# M55M1 register map
File version: 1.0
Registers are 32-bit, read-write, reset 0x0 unless marked. A register's access mark holds for its fields unless they carry their own. Offsets are from the block's base; [hi:lo] are bit positions.

## HSOTG_NS — HSOTG Register Map
Base 0x50259000
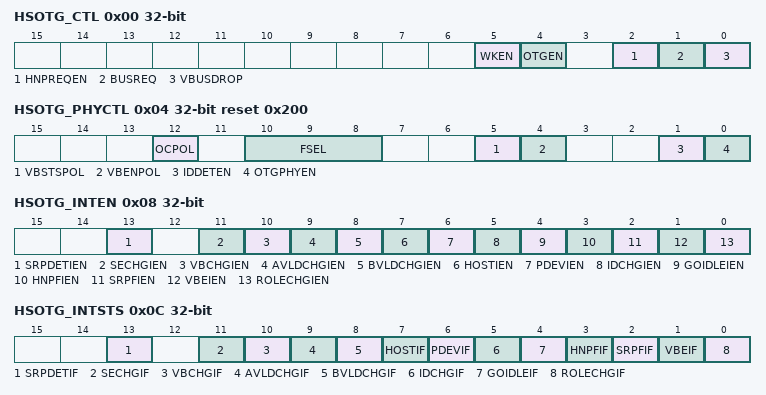
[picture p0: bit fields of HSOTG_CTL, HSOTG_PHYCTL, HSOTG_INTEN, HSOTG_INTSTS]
0x00 HSOTG_CTL — HSOTG Control Register
  [5] WKEN — OTG ID Pin Wake-up Enable Bit
    0=OTG ID pin status change wake-up function Disabled; 1=OTG ID pin status change wake-up function Enabled
  [4] OTGEN — OTG Function Enable Bit. User needs to set this bit to enable OTG function while the USB frame configured as OTG device. When the USB frame is not configured as OTG device, this bit is must be low.
    0=OTG function Disabled; 1=OTG function Enabled
  [2] HNPREQEN — OTG HNP Request Enable Bit. When the USB frame acts as A-device, set this bit when A-device allows to process HNP protocolA-device changes role from Host to Peripheral. This bit will be cleared when OTG state changes from a_suspend to a_peripheral or goes back to a_idle state. When the USB frame acts as B-device, set this bit after the OTG A-device successfully sends a SetFeature (b_hnp_enable) command to the OTG B-device to start role changeB-device changes role from Peripheral to Host. This bit will be cleared when OTG state changes from b_peripheral to b_wait_acon or goes back to b_idle state. Note: Refer to OTG specification to get a_suspend, a_peripheral, a_idle and b_idle state.
    0=HNP request Disabled; 1=HNP request Enabled (A-device can change role from Host to Peripheral or B-device can change role from Peripheral to Host)
  [1] BUSREQ — OTG Bus Request. If OTG A-device wants to do data transfers via USB bus, setting this bit will drive VBUS high to detect USB device connection. If user won't use the bus any more, clearing this bit will drop VBUS to save power. This bit will be cleared when A-device goes to A_wait_vfall state. This bit will be also cleared if VBUSDROP (HSOTG_CTL[0]) bit is set or IDSTS (HSOTG_STATUS[1]) changed. If user of an OTG-B Device wants to request VBUS, setting this bit will run SRP protocol. This bit will be cleared if SRP failure (OTG A-device does not provide VBUS after B-device issues SRP in specified interval, defined in OTG specification). This bit will be also cleared if VBUSDROP (HSOTG_CTL[0]) bit is set or IDSTS (HSOTG_STATUS[1]) changed.
    0=Not launch VBUS in OTG A-device or not request SRP in OTG B-device; 1=Launch VBUS in OTG A-device or request SRP in OTG B-device
  [0] VBUSDROP — Drop VBUS Control. If user application running on this OTG A-device wants to conserve power, set this bit to drop VBUS. BUSREQ (HSOTG_CTL[1]) will be also cleared no matter A-device or B-device.
    0=Not drop the VBUS; 1=Drop the VBUS
0x04 HSOTG_PHYCTL reset 0x200 — HSOTG PHY Control Register
  [12] OCPOL — Over Current Polarity. The polarity of off-chip USB VBUS power switch's overcurrent signal depends on the selected component. A USB_VBUS_ST pin is used to monitor the signal of the off-chip USB VBUS power switch's overcurrent signal.Set this bit as following according to the polarity of off-chip USB VBUS power switch's overcurrent. The overcurrent signal be used in USB HOST.
    0=The polarity of off-chip USB VBUS power switch's overcurrent is low; 1=The polarity of off-chip USB VBUS power switch's overcurrent is high
  [10:8] FSEL — Reference Clock Frequency Select. Selects OTG PHY reference clock frequency .
    0=Reference clock is 19.2 MHz; 1=Reference clock is 20 MHz; 2=Reference clock is 24 MHz; 3=Reference clock is 16 MHz; 6=Reference clock is 26MHz; 7=Reference clock is 32 MHz
  [5] VBSTSPOL — Off-chip USB VBUS Power Switch Status Polarity. The polarity of off-chip USB VBUS power switch valid signal depends on the selected component. A USB_VBUS_ST pin is used to monitor the valid signal of the off-chip USB VBUS power switch. Set this bit as following according to the polarity of off-chip USB VBUS power switch.
    0=The polarity of off-chip USB VBUS power switch valid status is high; 1=The polarity of off-chip USB VBUS power switch valid status is low
  [4] VBENPOL — Off-chip USB VBUS Power Switch Enable Polarity. The OTG controller will enable off-chip USB VBUS power switch to provide VBUS power when need. A USB_VBUS_EN pin is used to control the off-chip USB VBUS power switch. The polarity of enabling off-chip USB VBUS power switch (high active or low active) depends on the selected component. Set this bit as following according to the polarity of off-chip USB VBUS power switch.
    0=The off-chip USB VBUS power switch enable is active high; 1=The off-chip USB VBUS power switch enable is active low
  [1] IDDETEN — ID Detection Enable Bit
    0=Detect ID pin status Disabled; 1=Detect ID pin status Enabled
  [0] OTGPHYEN — OTG PHY Enable Bit. When the USB frame is configured as either OTG device or ID dependent, user needs to set this bit before using OTG function. If device is configured as neither OTG device nor ID dependent, this bit is 'don't care'.
    0=OTG PHY Disabled; 1=OTG PHY Enabled
0x08 HSOTG_INTEN — HSOTG Interrupt Enable Register
  [13] SRPDETIEN — SRP Detected Interrupt Enable Bit
    0=Interrupt Disabled; 1=Interrupt Enabled
  [11] SECHGIEN — SESSEND Status Changed Interrupt Enable Bit. If this bit is set to 1 and SESSEND (HSOTG_STATUS[2]) status is changed from high to low or from low to high, an interrupt will be asserted.
    0=Interrupt Disabled; 1=Interrupt Enabled
  [10] VBCHGIEN — VBUSVLD Status Changed Interrupt Enable Bit. If this bit is set to 1 and VBUSVLD (HSOTG_STATUS[5]) status is changed from high to low or from low to high, an interrupt will be asserted.
    0=Interrupt Disabled; 1=Interrupt Enabled
  [9] AVLDCHGIEN — A-device Session Valid Status Changed Interrupt Enable Bit. If this bit is set to 1 and AVLD (HSOTG_STATUS[4]) status is changed from high to low or from low to high, an interrupt will be asserted.
    0=Interrupt Disabled; 1=Interrupt Enabled
  [8] BVLDCHGIEN — B-device Session Valid Status Changed Interrupt Enable Bit. If this bit is set to 1 and BVLD (HSOTG_STATUS[3]) status is changed from high to low or from low to high, an interrupt will be asserted.
    0=Interrupt Disabled; 1=Interrupt Enabled
  [7] HOSTIEN — Act As Host Interrupt Enable Bit. If this bit is set to 1 and the device is changed as a host, an interrupt will be asserted.
    0=This device as a host interrupt Disabled; 1=This device as a host interrupt Enabled
  [6] PDEVIEN — Act As Peripheral Interrupt Enable Bit. If this bit is set to 1 and the device is changed as a peripheral, an interrupt will be asserted.
    0=This device as a peripheral interrupt Disabled; 1=This device as a peripheral interrupt Enabled
  [5] IDCHGIEN — IDSTS Changed Interrupt Enable Bit. If this bit is set to 1 and IDSTS (HSOTG_STATUS[1]) status is changed from high to low or from low to high, an interrupt will be asserted.
    0=Interrupt Disabled; 1=Interrupt Enabled
  [4] GOIDLEIEN — OTG Device Going to IDLE State Interrupt Enable Bit. Note: Going to idle state means going to a_idle or b_idle state. Please refer to A-device state diagram and B-device state diagram in OTG specification.
    0=Interrupt Disabled; 1=Interrupt Enabled
  [3] HNPFIEN — HNP Fail Interrupt Enable Bit
    0=Interrupt Disabled; 1=Interrupt Enabled
  [2] SRPFIEN — SRP Fail Interrupt Enable Bit
    0=Interrupt Disabled; 1=Interrupt Enabled
  [1] VBEIEN — VBUS Error Interrupt Enable Bit. Note: VBUS error means going to a_vbus_err state. Please refer to A-device state diagram in OTG specification.
    0=Interrupt Disabled; 1=Interrupt Enabled
  [0] ROLECHGIEN — Role Changed Interrupt Enable Bit. Note: The role can be Host or Peripheral.
    0=Interrupt Disabled; 1=Interrupt Enabled
0x0C HSOTG_INTSTS (reset mask 0xFFFFF00F) — HSOTG Interrupt Status Register
  [13] SRPDETIF — SRP Detected Interrupt Status. Note: Write 1 to clear this status.
    0=SRP not detected; 1=SRP detected
  [11] SECHGIF — SESSEND State Change Interrupt Status. Note: Write 1 to clear this flag.
    0=SESSEND (HSOTG_STATUS[2]) not toggled; 1=SESSEND (HSOTG_STATUS[2]) from high to low or from low to high
  [10] VBCHGIF — VBUSVLD State Change Interrupt Status. Note: Write 1 to clear this status.
    0=VBUSVLD (HSOTG_STATUS[5]) not toggled; 1=VBUSVLD (HSOTG_STATUS[5]) from high to low or from low to high
  [9] AVLDCHGIF — A-device Session Valid State Change Interrupt Status. Note: Write 1 to clear this status.
    0=AVLD (HSOTG_STATUS[4]) not toggled; 1=AVLD (HSOTG_STATUS[4]) from high to low or low to high
  [8] BVLDCHGIF — B-device Session Valid State Change Interrupt Status. Note: Write 1 to clear this status.
    0=BVLD (HSOTG_STATUS[3]) not toggled; 1=BVLD (HSOTG_STATUS[3]) from high to low or low to high
  [7] HOSTIF — Act As Host Interrupt Status. Note: Write 1 to clear this flag.
    0=This device does not act as a host; 1=This device acts as a host
  [6] PDEVIF — Act As Peripheral Interrupt Status. Note: Write 1 to clear this flag.
    0=This device does not act as a peripheral; 1=This device acts as a peripheral
  [5] IDCHGIF — ID State Change Interrupt Status. Note: Write 1 to clear this flag.
    0=IDSTS (HSOTG_STATUS[1]) not toggled; 1=IDSTS (HSOTG_STATUS[1]) from high to low or from low to high
  [4] GOIDLEIF — OTG Device Goes to IDLE Interrupt Status. Flag is set if the OTG device transfers from non-idle state to idle state. The OTG device will be neither a host nor a peripheral. Note 1: Going to idle state means going to a_idle or b_idle state. Please refer to OTG specification. Note 2: Write 1 to clear this flag.
    0=OTG device does not go back to idle state (a_idle or b_idle); 1=OTG device goes back to idle state(a_idle or b_idle)
  [3] HNPFIF — HNP Fail Interrupt Status. When A-device has granted B-device to be host and USB bus is in SE0 (both HSUSB_D+ and HSUSB_D- low) state, this bit will be set when A-device does not connect after specified interval expires. Note: Write 1 to clear this flag.
    0=A-device connects to B-device before specified interval expires; 1=A-device does not connect to B-device before specified interval expires
  [2] SRPFIF — SRP Fail Interrupt Status. After initiating SRP, an OTG B-device will wait for the OTG A-device to drive VBUS high at least TB_SRP_FAIL minimum, defined in OTG specification. This flag is set when the OTG B-device does not get VBUS high after this interval. Note: Write 1 to clear this flag.
    0=OTG B-device gets VBUS high before this interval; 1=OTG B-device does not get VBUS high before this interval
  [1] VBEIF — VBUS Error Interrupt Status. This bit will be set when voltage on VBUS cannot reach a minimum valid threshold 4.4V within a maximum time of 100ms after OTG A-device starting to drive VBUS high. Note: Write 1 to clear this flag and recover from the VBUS error state.
    0=OTG A-device drives VBUS over threshold voltage before this interval expires; 1=OTG A-device cannot drive VBUS over threshold voltage before this interval expires
  [0] ROLECHGIF — OTG Role Change Interrupt Status. This flag is set when the role of an OTG device changed from a host to a peripheral, or changed from a peripheral to a host while USB_ID pin status does not change. Note: Write 1 to clear this flag.
    0=OTG device role not changed; 1=OTG device role changed
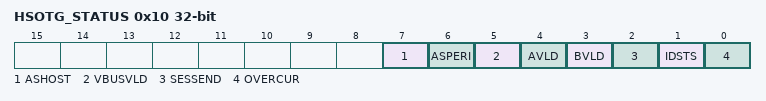
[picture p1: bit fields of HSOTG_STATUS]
0x10 HSOTG_STATUS ro (reset mask 0xFFFFFFF0)
  [7] ASHOST — As Host Status. When OTG acts as Host, this bit is set.
    0=OTG not as Host; 1=OTG as Host
  [6] ASPERI — As Peripheral Status. When OTG acts as peripheral, this bit is set.
    0=OTG not as peripheral; 1=OTG as peripheral
  [5] VBUSVLD — VBUS Valid Status. When VBUS is larger than 4.7V, this bit will be set to 1.
    0=VBUS is not valid; 1=VBUS is valid
  [4] AVLD — A-Device Session Valid Status
    0=A-device session is not valid; 1=A-device session is valid
  [3] BVLD — B-device Session Valid Status
    0=B-device session is not valid; 1=B-device session is valid
  [2] SESSEND — Session End Status. When VBUS voltage is lower than 0.4V, this bit will be set to 1. Session end means no meaningful power on VBUS.
    0=Session is not end; 1=Session is end
  [1] IDSTS — USB_ID Pin State of Mini-/Micro-Plug
    0=Mini-A/Micro-A plug is attached; 1=Mini-B/Micro-B plug is attached
  [0] OVERCUR — Overcurrent Condition. The voltage on VBUS cannot reach a minimum VBUS valid threshold, 4.4V minimum, within a maximum time of 100ms after OTG A-device drives VBUS high.
    0=OTG A-device drives VBUS successfully; 1=OTG A-device cannot drive VBUS high in this interval
